# RE01_1500KB register map
Vendor: Renesas Electronics Corporation; Series: RE01_1500KB; File version: 1.20
CPU: CM0PLUS r0p1, little endian, MPU, no FPU, VTOR, 2 interrupt priority bits
Registers are 8-bit, read-write, reset 0x0 unless marked. A register's access mark holds for its fields unless they carry their own. Offsets are from the block's base; [hi:lo] are bit positions; {n}, {i} and the like mark numbered series; 'fields as' and 'values as' point back to an identical list.

## MMF — Memory Mirror Function
Base 0x40001000
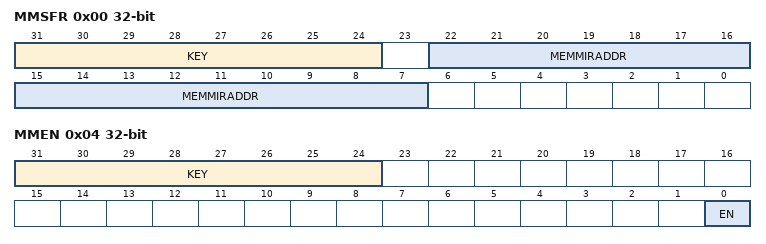
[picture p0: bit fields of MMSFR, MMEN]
0x00 MMSFR 32-bit — MemMirror Special Function Register
  [31:24] KEY — MMSFR Key Code
    219=Writing to the MEMMIRADDR bits are valid, when the KEY bits are written 0xDB; other=others (Writing to the MEMMIRADDR bits are invalid.)
  [22:7] MEMMIRADDR — Specifies the memory mirror address.
0x04 MMEN 32-bit — MemMirror Enable Register
  [31:24] KEY — MMEN Key Code
    219=Writing to the EN bit is valid, when the KEY bits are written 0xDB; other=others (Writing to the EN bit is invalid.)
  [0] EN — Memory Mirror Function Enable
    0=Memory Mirror Function is disabled; 1=Memory Mirror Function is enabled

## MMPU — Bus Master MPU
Base 0x40000000
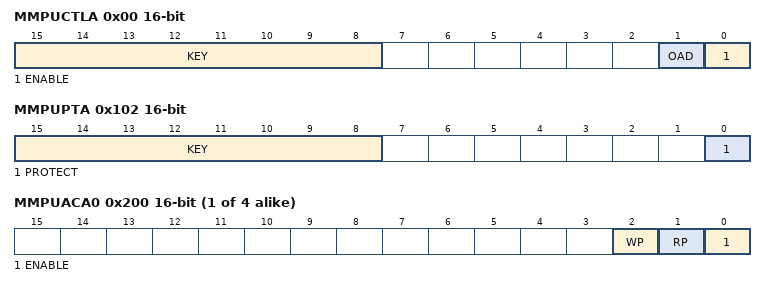
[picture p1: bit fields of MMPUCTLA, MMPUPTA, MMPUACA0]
0x00 MMPUCTLA 16-bit — Bus Master MPU Control Register
  [15:8] KEY — Write Keyword The data written to these bits are not stored.
    165=Writing to the OAD and ENABLE bit is valid, when the KEY bits are written 0xA5; other=others (Writing to the OAD and ENABLE bit is invalid.)
  [1] OAD — Operation After Detection
    0=Non-maskable interrupt; 1=Internal reset
  [0] ENABLE — Master Group Enable
    0=Master Group A disabled. Permission of all regions.; 1=Master Group A enabled. Protection of all regions.
0x102 MMPUPTA 16-bit — Group A Protection of Register
  [15:8] KEY — Write Keyword The data written to these bits are not stored.
    165=Writing to the PROTECT bit is valid, when the KEY bits are written 0xA5; other=others (Writing to the PROTECT bit is invalid.)
  [0] PROTECT — Protection of register(MMPUSAn, MMPUEAn, MMPUACAn and MMPUCTLA )
    0=All Bus Master MPU Group A register writing is possible; 1=All Bus Master MPU Group A register writing is protected. Read is possible.
{0x200+0x10*i} MMPUACA{i} (i=0..3) 16-bit — Group A Region {i} Access Control Register
  [2] WP — Write protection
    0=Write permission; 1=Write protection
  [1] RP — Read protection
    0=Read permission; 1=Read protection
  [0] ENABLE — Region enable
    0=Group A Region n unit is disabled; 1=Group A Region n unit is enabled
{0x204+0x10*i} MMPUSA{i} 32-bit (reset mask 0x3) (i=0..3) — Group A Region {i} Start Address Register
  [31:0] MMPUSA{i} — Region Start Address : Address where the region starts, for use in region determination.NOTE: The low-order 2 bits are fixed to 0.
{0x208+0x10*i} MMPUEA{i} 32-bit reset 0x3 (reset mask 0x3) (i=0..3) — Group A Region {i} End Address Register
  [31:0] MMPUEA{i} — Region End Address : Address where the region ends, for use in region determination.NOTE: The low-order 2 bits are fixed to 0.

## MSTP — Module Stop Control B,C,D
Base 0x40047000
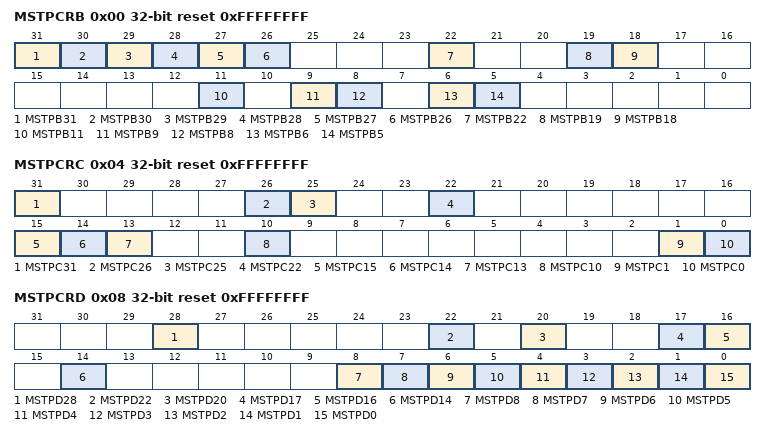
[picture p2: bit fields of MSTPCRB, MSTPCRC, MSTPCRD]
0x00 MSTPCRB 32-bit reset 0xFFFFFFFF — Module Stop Control Register B
  [all] fields
    0=Cancel the module-stop state; 1=Enter the module-stop state
  [31] MSTPB31 — Serial Communication Interface 0 Module Stop
  [30] MSTPB30 — Serial Communication Interface 1 Module Stop
  [29] MSTPB29 — Serial Communication Interface 2 Module Stop
  [28] MSTPB28 — Serial Communication Interface 3 Module Stop
  [27] MSTPB27 — Serial Communication Interface 4 Module Stop
  [26] MSTPB26 — Serial Communication Interface 5 Module Stop
  [22] MSTPB22 — Serial Communication Interface 9 Module Stop
  [19] MSTPB19 — Serial Peripheral Interface 0 Module Stop
  [18] MSTPB18 — Serial Peripheral Interface 1 Module Stop
  [11] MSTPB11 — Universal Serial Bus 2.0 FS Interface Module Stop
  [9] MSTPB9 — I2C Bus Interface 0 Module Stop
  [8] MSTPB8 — I2C Bus Interface 1 Module Stop
  [6] MSTPB6 — Quad Peripheral Interface Module Stop
  [5] MSTPB5 — Infrared Data Association Interface Module Stop
0x04 MSTPCRC 32-bit reset 0xFFFFFFFF — Module Stop Control Register C
  [31] MSTPC31
    values as the fields of MSTPCRB
  [26] MSTPC26
    values as the fields of MSTPCRB
  [25] MSTPC25
    values as the fields of MSTPCRB
  [22] MSTPC22
    values as the fields of MSTPCRB
  [15] MSTPC15
    values as the fields of MSTPCRB
  [14] MSTPC14 — Event Link Controller Module Stop
    values as the fields of MSTPCRB
  [13] MSTPC13 — Data Operation Circuit Module Stop
    values as the fields of MSTPCRB
  [10] MSTPC10
  [1] MSTPC1 — CRC Calculator Module Stop
    values as the fields of MSTPCRB
  [0] MSTPC0 — CAC Module Stop
    values as the fields of MSTPCRB
0x08 MSTPCRD 32-bit reset 0xFFFFFFFF — Module Stop Control Register D
  [28] MSTPD28
    values as the fields of MSTPCRB
  [22] MSTPD22
    values as the fields of MSTPCRB
  [20] MSTPD20
    values as the fields of MSTPCRB
  [17] MSTPD17
    values as the fields of MSTPCRB
  [16] MSTPD16
    values as the fields of MSTPCRB
  [14] MSTPD14
    values as the fields of MSTPCRB
  [8] MSTPD8
  [7] MSTPD7
    values as the fields of MSTPCRB
  [6] MSTPD6 — GPT ch160 - ch163 Module Stop
    values as the fields of MSTPCRB
  [5] MSTPD5 — GPT ch320 - ch321 Module Stop
    values as the fields of MSTPCRB
  [4] MSTPD4
  [3] MSTPD3
    values as the fields of MSTPCRB
  [2] MSTPD2
    values as the fields of MSTPCRB
  [1] MSTPD1
    values as the fields of MSTPCRB
  [0] MSTPD0
